# ESP32-P4 register map
Vendor: ESPRESSIF SYSTEMS (SHANGHAI) CO., LTD.; Series: ESP32 P-Series; File version: 3
CPU: RV32IMAFC r0p0, little endian, no MPU, FPU, 0 interrupt priority bits
Address unit: 32 bits
Registers are 32-bit, read-write, reset 0x0 unless marked. A register's access mark holds for its fields unless they carry their own. Offsets are from the block's base; [hi:lo] are bit positions.

## PPA — PPA Peripheral
Base 0x50087000
0x00 BLEND0_CLUT_DATA — CLUT sram data read/write register in background plane of blender
  [31:0] RDWR_WORD_BLEND0_CLUT — Write and read data to/from CLUT RAM in background plane of blender engine through this field in fifo mode.
0x04 BLEND1_CLUT_DATA — CLUT sram data read/write register in foreground plane of blender
  [31:0] RDWR_WORD_BLEND1_CLUT — Write and read data to/from CLUT RAM in foreground plane of blender engine through this field in fifo mode.
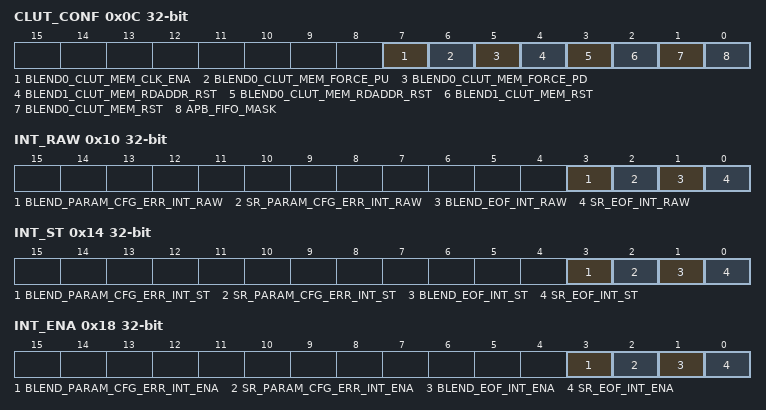
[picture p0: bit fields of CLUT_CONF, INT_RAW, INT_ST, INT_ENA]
0x0C CLUT_CONF — CLUT configure register
  [7] BLEND0_CLUT_MEM_CLK_ENA — 1: Force clock on for BLEND CLUT memory.
  [6] BLEND0_CLUT_MEM_FORCE_PU — 1: force power up BLEND CLUT memory.
  [5] BLEND0_CLUT_MEM_FORCE_PD — 1: force power down BLEND CLUT memory.
  [4] BLEND1_CLUT_MEM_RDADDR_RST — Write 1 then write 0 to reset the read address of BLEND1 CLUT in fifo mode.
  [3] BLEND0_CLUT_MEM_RDADDR_RST — Write 1 then write 0 to reset the read address of BLEND0 CLUT in fifo mode.
  [2] BLEND1_CLUT_MEM_RST — Write 1 then write 0 to this bit to reset BLEND1 CLUT.
  [1] BLEND0_CLUT_MEM_RST — Write 1 then write 0 to this bit to reset BLEND0 CLUT.
  [0] APB_FIFO_MASK — 1'b0: fifo mode to wr/rd clut0/clut1 RAM through register PPA_SR_CLUT_DATA_REG/PPA_BLEND0_CLUT_DATA_REG/PPA_BLEND1_CLUT_DATA_REG. 1'b1: memory mode to wr/rd sr/blend0/blend1 clut RAM. The bit 11 and 10 of the waddr should be 01 to access sr clut and should be 10 to access blend0 clut and should be 11 to access blend 1 clut in memory mode.
0x10 INT_RAW — Raw status interrupt
  [3] BLEND_PARAM_CFG_ERR_INT_RAW — The raw interrupt bit turns to high level when the configured blending coefficient is wrong. User can check the reasons through register PPA_BLEND_ST_REG.
  [2] SR_PARAM_CFG_ERR_INT_RAW — The raw interrupt bit turns to high level when the configured scaling and rotating coefficient is wrong. User can check the reasons through register PPA_SR_PARAM_ERR_ST_REG.
  [1] BLEND_EOF_INT_RAW — The raw interrupt bit turns to high level when blending engine calculate one frame image.
  [0] SR_EOF_INT_RAW — The raw interrupt bit turns to high level when scaling and rotating engine calculate one frame image.
0x14 INT_ST ro — Masked interrupt
  [3] BLEND_PARAM_CFG_ERR_INT_ST — The raw interrupt status bit for the PPA_BLEND_PARAM_CFG_ERR_INT interrupt.
  [2] SR_PARAM_CFG_ERR_INT_ST — The raw interrupt status bit for the PPA_SR_PARAM_CFG_ERR_INT interrupt.
  [1] BLEND_EOF_INT_ST — The raw interrupt status bit for the PPA_BLEND_EOF_INT interrupt.
  [0] SR_EOF_INT_ST — The raw interrupt status bit for the PPA_SR_EOF_INT interrupt.
0x18 INT_ENA — Interrupt enable bits
  [3] BLEND_PARAM_CFG_ERR_INT_ENA — The interrupt enable bit for the PPA_BLEND_PARAM_CFG_ERR_INT interrupt.
  [2] SR_PARAM_CFG_ERR_INT_ENA — The interrupt enable bit for the PPA_SR_PARAM_CFG_ERR_INT interrupt.
  [1] BLEND_EOF_INT_ENA — The interrupt enable bit for the PPA_BLEND_EOF_INT interrupt.
  [0] SR_EOF_INT_ENA — The interrupt enable bit for the PPA_SR_EOF_INT interrupt.
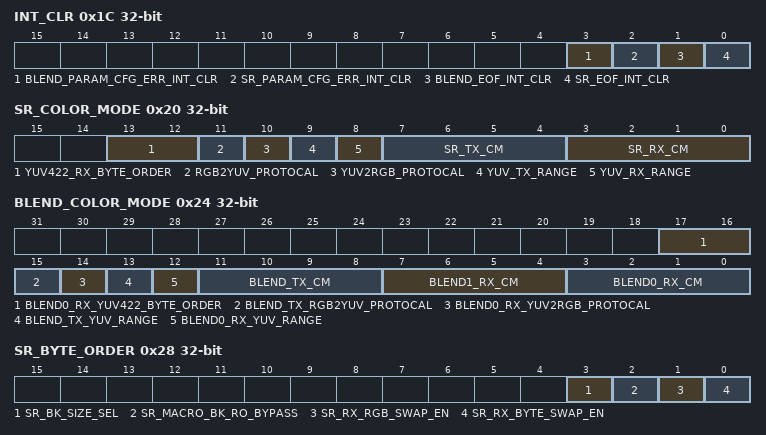
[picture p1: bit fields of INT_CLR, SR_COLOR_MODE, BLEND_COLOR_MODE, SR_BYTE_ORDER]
0x1C INT_CLR wo — Interrupt clear bits
  [3] BLEND_PARAM_CFG_ERR_INT_CLR — Set this bit to clear the PPA_BLEND_PARAM_CFG_ERR_INT interrupt.
  [2] SR_PARAM_CFG_ERR_INT_CLR — Set this bit to clear the PPA_SR_RX_YSCAL_ERR_INT interrupt.
  [1] BLEND_EOF_INT_CLR — Set this bit to clear the PPA_BLEND_EOF_INT interrupt.
  [0] SR_EOF_INT_CLR — Set this bit to clear the PPA_SR_EOF_INT interrupt.
0x20 SR_COLOR_MODE — Scaling and rotating engine color mode register
  [13:12] YUV422_RX_BYTE_ORDER — YUV422 input byte order when reg_sr_rx_cm is 4'd9. 0: YVYU, 1:YUYV, 2: VYUY, 3: UYVY
  [11] RGB2YUV_PROTOCAL — RGB to YUV protocal when reg_sr_tx_cm is 4'd8. 0: BT601. 1: BT709
  [10] YUV2RGB_PROTOCAL — YUV to RGB protocal when reg_sr_rx_cm is 4'd8. 0: BT601. 1: BT709
  [9] YUV_TX_RANGE — YUV output range when reg_sr_tx_cm is 4'd8. 0: limit range. 1: full range
  [8] YUV_RX_RANGE — YUV input range when reg_sr_rx_cm is 4'd8. 0: limit range. 1: full range
  [7:4] SR_TX_CM — The destination image color mode for Scaling and Rotating engine Tx. 0: ARGB8888. 1: RGB888. 2: RGB565. 8: YUV420. 9: YUV422. 12: GRAY. others: Reserved.
  [3:0] SR_RX_CM — The source image color mode for Scaling and Rotating engine Rx. 0: ARGB8888. 1: RGB888. 2: RGB565. 8: YUV420. 9: YUV422. 12: GRAY. others: Reserved.
0x24 BLEND_COLOR_MODE — blending engine color mode register
  [17:16] BLEND0_RX_YUV422_BYTE_ORDER — YUV422 input byte order when reg_sr_rx_cm is 4'd9. 0: YVYU, 1:YUYV, 2: VYUY, 3: UYVY
  [15] BLEND_TX_RGB2YUV_PROTOCAL — RGB to YUV protocal when blend tx cm is yuv. 0: BT601. 1: BT709
  [14] BLEND0_RX_YUV2RGB_PROTOCAL — YUV to RGB protocal when blend0 rx cm is yuv. 0: BT601. 1: BT709
  [13] BLEND_TX_YUV_RANGE — YUV output range when blend tx cm is yuv. 0: limit range. 1: full range
  [12] BLEND0_RX_YUV_RANGE — YUV input range when blend0 rx cm is yuv. 0: limit range. 1: full range
  [11:8] BLEND_TX_CM — The destination image color mode for output of blender. 0: ARGB8888. 1: RGB888. 2: RGB565. 3: Reserved. 8: YUV420. 9: YUV422. 12:GRAY
  [7:4] BLEND1_RX_CM — The source image color mode for foreground plane. 0: ARGB8888. 1: RGB888. 2: RGB565. 3: Reserved. 4: L8. 5: L4. 6: A8. 7: A4.
  [3:0] BLEND0_RX_CM — The source image color mode for background plane. 0: ARGB8888. 1: RGB888. 2: RGB565. 3: Reserved. 4: L8. 5: L4. 8: YUV420. 9: YUV422. 12:GRAY
0x28 SR_BYTE_ORDER — Scaling and rotating engine byte order register
  [3] SR_BK_SIZE_SEL — sel srm pix_blk size, 0:32x32, 1:16x16
  [2] SR_MACRO_BK_RO_BYPASS — Set this bit to 1 to bypass the macro block order function. This function is used to improve efficient accessing external memory.
  [1] SR_RX_RGB_SWAP_EN — Set this bit to 1 the data into Rx channel 0 would be swapped in rgb. It means rgb would be swap to bgr.
  [0] SR_RX_BYTE_SWAP_EN — Set this bit to 1 the data into Rx channel 0 would be swapped in byte. The Byte0 and Byte1 would be swapped while byte 2 and byte 3 would be swappped.
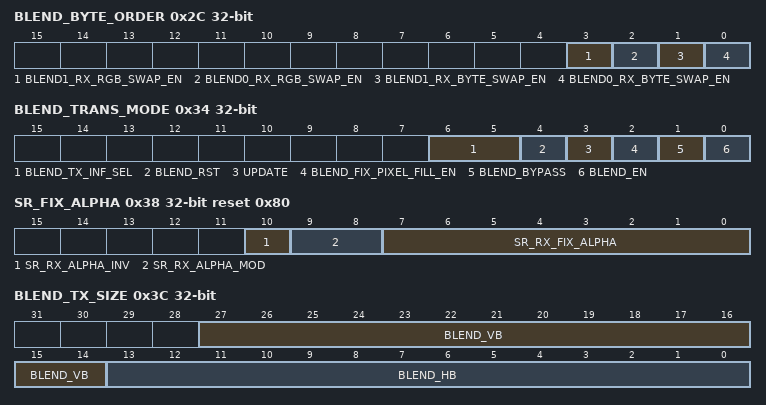
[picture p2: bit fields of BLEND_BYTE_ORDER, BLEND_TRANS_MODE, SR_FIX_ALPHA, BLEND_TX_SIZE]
0x2C BLEND_BYTE_ORDER — Blending engine byte order register
  [3] BLEND1_RX_RGB_SWAP_EN — Set this bit to 1 the data into Rx channel 0 would be swapped in rgb. It means rgb would be swap to bgr.
  [2] BLEND0_RX_RGB_SWAP_EN — Set this bit to 1 the data into Rx channel 0 would be swapped in rgb. It means rgb would be swap to bgr.
  [1] BLEND1_RX_BYTE_SWAP_EN — Set this bit to 1 the data into Rx channel 0 would be swapped in byte. The Byte0 and Byte1 would be swapped while byte 2 and byte 3 would be swappped.
  [0] BLEND0_RX_BYTE_SWAP_EN — Set this bit to 1 the data into Rx channel 0 would be swapped in byte. The Byte0 and Byte1 would be swapped while byte 2 and byte 3 would be swappped.
0x34 BLEND_TRANS_MODE access per field — Blending engine mode configure register
  [6:5] BLEND_TX_INF_SEL rw — unused ! Configures blend tx interface. 0: dma2d only, 1: le_enc only, 2: dma2d and ls_enc
  [4] BLEND_RST rw — write 1 then write 0 to reset blending engine.
  [3] UPDATE wo — Set this bit to update the transfer mode. Only the bit is set the transfer mode is valid.
  [2] BLEND_FIX_PIXEL_FILL_EN rw — This bit is used to enable fix pixel filling. When this mode is enable only Tx channel is work and the output pixel is configured by PPA_OUT_FIX_PIXEL.
  [1] BLEND_BYPASS rw — Set this bit to bypass blender. Then background date would be output.
  [0] BLEND_EN rw — Set this bit to enable alpha blending.
0x38 SR_FIX_ALPHA reset 0x80 — Scaling and rotating engine alpha override register
  [10] SR_RX_ALPHA_INV — Set this bit to invert the original alpha value. When RX color mode is RGB565/RGB88. The original alpha value is 255.
  [9:8] SR_RX_ALPHA_MOD — Alpha mode. 0/3: not replace alpha. 1: replace alpha with PPA_SR_FIX_ALPHA. 2: Original alpha multiply with PPA_SR_FIX_ALPHA/256.
  [7:0] SR_RX_FIX_ALPHA — The value would replace the alpha value in received pixel for Scaling and Rotating engine when PPA_SR_RX_ALPHA_CONF_EN is enabled.
0x3C BLEND_TX_SIZE — Fix pixel filling mode image size register
  [27:14] BLEND_VB — The vertical width of image block that would be filled in fix pixel filling mode or blend mode. The unit is pixel. Must be even num when YUV420
  [13:0] BLEND_HB — The horizontal width of image block that would be filled in fix pixel filling mode or blend mode. The unit is pixel. Must be even num when YUV422 or YUV420
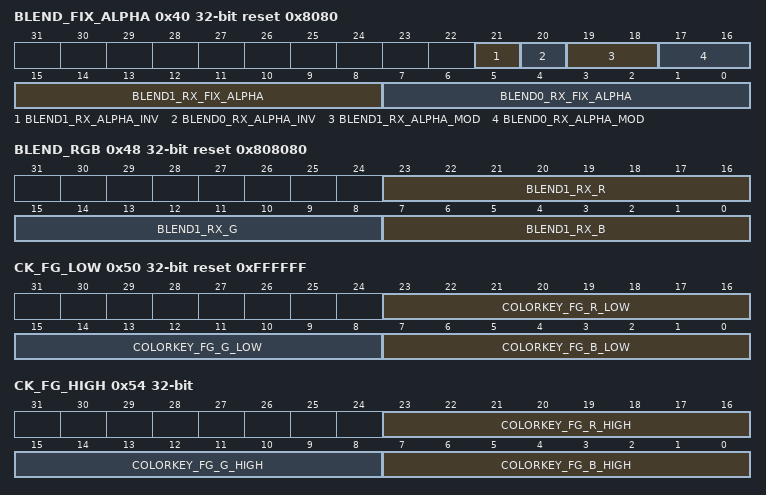
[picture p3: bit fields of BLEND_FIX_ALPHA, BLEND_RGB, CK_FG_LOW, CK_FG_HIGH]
0x40 BLEND_FIX_ALPHA reset 0x8080 — Blending engine alpha override register
  [21] BLEND1_RX_ALPHA_INV — Set this bit to invert the original alpha value. When RX color mode is RGB565/RGB88. The original alpha value is 255.
  [20] BLEND0_RX_ALPHA_INV — Set this bit to invert the original alpha value. When RX color mode is RGB565/RGB88. The original alpha value is 255.
  [19:18] BLEND1_RX_ALPHA_MOD — Alpha mode. 0/3: not replace alpha. 1: replace alpha with PPA_BLEND1_FIX_ALPHA. 2: Original alpha multiply with PPA_SR_FIX_ALPHA/256.
  [17:16] BLEND0_RX_ALPHA_MOD — Alpha mode. 0/3: not replace alpha. 1: replace alpha with PPA_BLEND0_FIX_ALPHA. 2: Original alpha multiply with PPA_SR_FIX_ALPHA/256.
  [15:8] BLEND1_RX_FIX_ALPHA — The value would replace the alpha value in received pixel for foreground plane of blender when PPA_BLEND1_RX_ALPHA_CONF_EN is enabled.
  [7:0] BLEND0_RX_FIX_ALPHA — The value would replace the alpha value in received pixel for background plane of blender when PPA_BLEND0_RX_ALPHA_CONF_EN is enabled.
0x48 BLEND_RGB reset 0x808080 — RGB color register
  [23:16] BLEND1_RX_R — red color for A4/A8 mode.
  [15:8] BLEND1_RX_G — green color for A4/A8 mode.
  [7:0] BLEND1_RX_B — blue color for A4/A8 mode.
0x4C BLEND_FIX_PIXEL — Blending engine fix pixel register
  [31:0] BLEND_TX_FIX_PIXEL — The configure fix pixel in fix pixel filling mode for blender engine.
0x50 CK_FG_LOW reset 0xFFFFFF — foreground color key lower threshold
  [23:16] COLORKEY_FG_R_LOW — color key lower threshold of foreground r channel
  [15:8] COLORKEY_FG_G_LOW — color key lower threshold of foreground g channel
  [7:0] COLORKEY_FG_B_LOW — color key lower threshold of foreground b channel
0x54 CK_FG_HIGH — foreground color key higher threshold
  [23:16] COLORKEY_FG_R_HIGH — color key higher threshold of foreground r channel
  [15:8] COLORKEY_FG_G_HIGH — color key higher threshold of foreground g channel
  [7:0] COLORKEY_FG_B_HIGH — color key higher threshold of foreground b channel
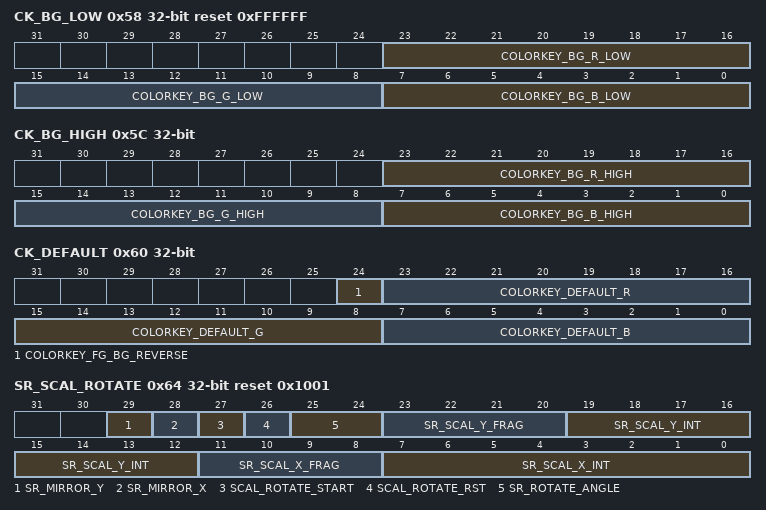
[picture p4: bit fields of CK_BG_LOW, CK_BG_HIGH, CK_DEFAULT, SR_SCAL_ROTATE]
0x58 CK_BG_LOW reset 0xFFFFFF — background color key lower threshold
  [23:16] COLORKEY_BG_R_LOW — color key lower threshold of background r channel
  [15:8] COLORKEY_BG_G_LOW — color key lower threshold of background g channel
  [7:0] COLORKEY_BG_B_LOW — color key lower threshold of background b channel
0x5C CK_BG_HIGH — background color key higher threshold
  [23:16] COLORKEY_BG_R_HIGH — color key higher threshold of background r channel
  [15:8] COLORKEY_BG_G_HIGH — color key higher threshold of background g channel
  [7:0] COLORKEY_BG_B_HIGH — color key higher threshold of background b channel
0x60 CK_DEFAULT — default value when foreground and background both in color key range
  [24] COLORKEY_FG_BG_REVERSE — when pixel in bg ck range but not in fg ck range, 0: the result is bg, 1: the result is fg
  [23:16] COLORKEY_DEFAULT_R — default R channle value of color key
  [15:8] COLORKEY_DEFAULT_G — default G channle value of color key
  [7:0] COLORKEY_DEFAULT_B — default B channle value of color key
0x64 SR_SCAL_ROTATE access per field reset 0x1001 — Scaling and rotating coefficient register
  [29] SR_MIRROR_Y rw — Image mirror in Y direction. 0: disable, 1: enable
  [28] SR_MIRROR_X rw — Image mirror in X direction. 0: disable, 1: enable
  [27] SCAL_ROTATE_START wo — Write 1 to enable scaling and rotating engine after parameter is configured.
  [26] SCAL_ROTATE_RST rw — Write 1 then write 0 to this bit to reset scaling and rotating engine.
  [25:24] SR_ROTATE_ANGLE rw — The rotate angle. 0: 0 degree. 1: 90 degree. 2: 180 degree. 3: 270 degree.
  [23:20] SR_SCAL_Y_FRAG rw — The fragment part of scaling coefficient in Y direction.
  [19:12] SR_SCAL_Y_INT rw — The integrated part of scaling coefficient in Y direction.
  [11:8] SR_SCAL_X_FRAG rw — The fragment part of scaling coefficient in X direction.
  [7:0] SR_SCAL_X_INT rw — The integrated part of scaling coefficient in X direction.
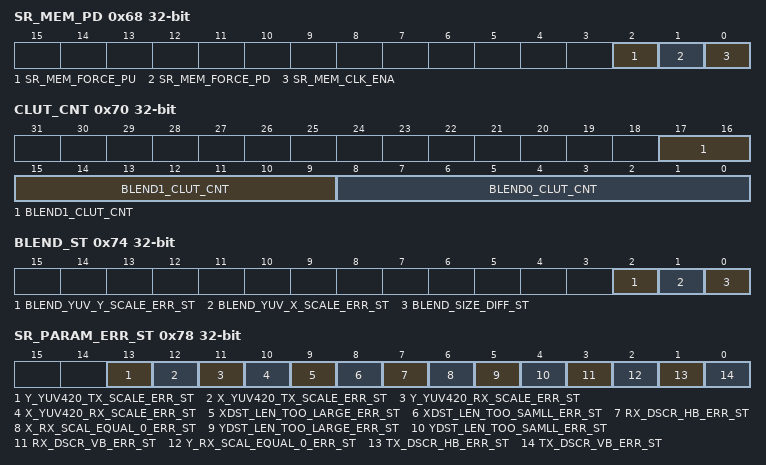
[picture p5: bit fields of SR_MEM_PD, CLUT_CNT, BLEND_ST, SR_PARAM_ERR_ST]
0x68 SR_MEM_PD — SR memory power done register
  [2] SR_MEM_FORCE_PU — Set this bit to force power up scaling and rotating engine's data memory.
  [1] SR_MEM_FORCE_PD — Set this bit to force power down scaling and rotating engine's data memory.
  [0] SR_MEM_CLK_ENA — Set this bit to force clock enable of scaling and rotating engine's data memory.
0x6C REG_CONF — Register clock enable register
  [0] CLK_EN — PPA register clock gate enable signal.
0x70 CLUT_CNT ro — BLEND CLUT write counter register
  [17:9] BLEND1_CLUT_CNT — The write data counter of BLEND1 CLUT in fifo mode.
  [8:0] BLEND0_CLUT_CNT — The write data counter of BLEND0 CLUT in fifo mode.
0x74 BLEND_ST ro — Blending engine status register
  [2] BLEND_YUV_Y_SCALE_ERR_ST — Represents that y param is an odd num when enable yuv420
  [1] BLEND_YUV_X_SCALE_ERR_ST — Represents that x param is an odd num when enable yuv422 or yuv420
  [0] BLEND_SIZE_DIFF_ST — 1: indicate the size of two image is different.
0x78 SR_PARAM_ERR_ST ro — Scaling and rotating coefficient error register
  [13] Y_YUV420_TX_SCALE_ERR_ST — The error is that the va/vb/y param in dma2d descriptor is an odd num when enable yuv420 tx
  [12] X_YUV420_TX_SCALE_ERR_ST — The error is that the ha/hb/x param in dma2d descriptor is an odd num when enable yuv422 or yuv420 tx
  [11] Y_YUV420_RX_SCALE_ERR_ST — The error is that the va/vb/y param in dma2d descriptor is an odd num when enable yuv420 rx
  [10] X_YUV420_RX_SCALE_ERR_ST — The error is that the ha/hb/x param in dma2d descriptor is an odd num when enable yuv422 or yuv420 rx
  [9] XDST_LEN_TOO_LARGE_ERR_ST — The error is that the scaled image height is larger than (2^13 - 1).
  [8] XDST_LEN_TOO_SAMLL_ERR_ST — The error is that the scaled image height is 0. For example. when source height is 14. scaled value is 1/16. and no rotate operation. then scaled height would be 0 as the result would be floored.
  [7] RX_DSCR_HB_ERR_ST — The error is that the HB in 2DDMA transmit descriptor plus the offset of X coordinate in 2DDMA transmit descriptor is larger than HA in 2DDMA transmit descriptor.
  [6] X_RX_SCAL_EQUAL_0_ERR_ST — The error is that the scaled image height is 0.
  [5] YDST_LEN_TOO_LARGE_ERR_ST — The error is that the scaled width is larger than (2^13 - 1).
  [4] YDST_LEN_TOO_SAMLL_ERR_ST — The error is that the scaled image width is 0. For example. when source width is 14. scaled value is 1/16. and no rotate operation. then scaled width would be 0 as the result would be floored.
  [3] RX_DSCR_VB_ERR_ST — The error is that VB in 2DDMA receive descriptor plus the offset of Y coordinate in 2DDMA transmit descriptor is larger than VA in 2DDMA transmit descriptor
  [2] Y_RX_SCAL_EQUAL_0_ERR_ST — The error is that the PPA_SR_SCAL_Y_INT and PPA_SR_CAL_Y_FRAG both are 0.
  [1] TX_DSCR_HB_ERR_ST — The error is that the scaled HB plus the offset of X coordinate in 2DDMA receive descriptor is larger than HA in 2DDMA receive descriptor.
  [0] TX_DSCR_VB_ERR_ST — The error is that the scaled VB plus the offset of Y coordinate in 2DDMA receive descriptor is larger than VA in 2DDMA receive descriptor.
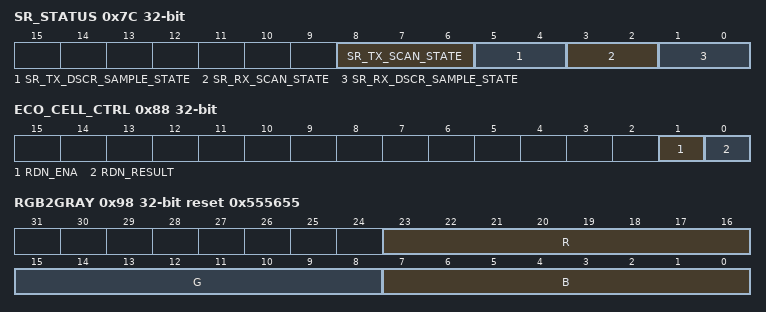
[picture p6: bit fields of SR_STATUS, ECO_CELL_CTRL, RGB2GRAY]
0x7C SR_STATUS ro — SR FSM register
  [8:6] SR_TX_SCAN_STATE — Reserved.
  [5:4] SR_TX_DSCR_SAMPLE_STATE — Reserved.
  [3:2] SR_RX_SCAN_STATE — Reserved.
  [1:0] SR_RX_DSCR_SAMPLE_STATE — Reserved.
0x80 ECO_LOW — Reserved.
  [31:0] RND_ECO_LOW
0x84 ECO_HIGH reset 0xFFFFFFFF — Reserved.
  [31:0] RND_ECO_HIGH
0x88 ECO_CELL_CTRL access per field — Reserved.
  [1] RDN_ENA rw — Reserved.
  [0] RDN_RESULT ro — Reserved.
0x8C SRAM_CTRL reset 0x1320 — PPA SRAM Control Register
  [13:0] MEM_AUX_CTRL — Control signals
0x90 DEBUG_CTRL0 — debug register
  [2:0] DBG_REPLACE_SEL — Configures the data replace location. 0: not replace, 1: srm rx input, 2: srm rx bilin interpolation, 3: srm tx output, 4: blend fg input, 5: blend bg input, 6: blend output
0x94 DEBUG_CTRL1 — debug register
  [31:0] DBG_REPLACE_DATA — Configures the replace data
0x98 RGB2GRAY reset 0x555655
  [23:16] R — Configures the r parameter for rgb2gray
  [15:8] G — Configures the g parameter for rgb2gray
  [7:0] B — Configures the b parameter for rgb2gray
0x100 DATE reset 0x20241220 — PPA Version register
  [31:0] DATE — register version.
